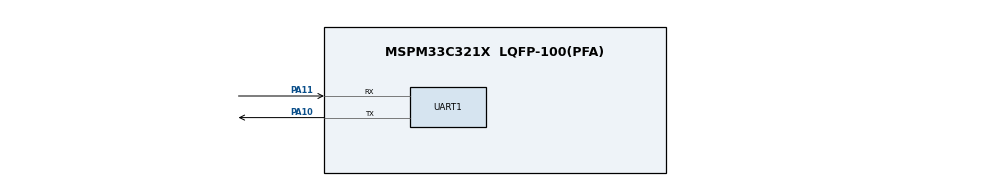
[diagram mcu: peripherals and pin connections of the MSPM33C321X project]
/**
 * @cliArgs --device "MSPM33C321X" --part "Default" --package "LQFP-100(PFA)" --product "mspm33_sdk@1.02.00.00"
 * @versions {"tool":"1.26.0+4407"}
 */
// @cliArgs --board /ti/boards/LP_MSPM33C321A --rtos nortos

/**
 * Import the modules used in this configuration.
 */
const DMA           = scripting.addModule("/ti/driverlib/DMA", {}, false);
const DMA1          = DMA.addInstance();
const GPIO          = scripting.addModule("/ti/driverlib/GPIO", {}, false);
const GPIO1         = GPIO.addInstance();
const HSADC         = scripting.addModule("/ti/driverlib/HSADC", {}, false);
const HSADC1        = HSADC.addInstance();
const SYSCTL        = scripting.addModule("/ti/driverlib/SYSCTL");
const TIMER         = scripting.addModule("/ti/driverlib/TIMER", {}, false);
const TIMER1        = TIMER.addInstance();
const UART          = scripting.addModule("/ti/driverlib/UART", {}, false);
const UART1         = UART.addInstance();
const ProjectConfig = scripting.addModule("/ti/project_config/ProjectConfig");

/**
 * Write custom configuration values to the imported modules.
 */
DMA1.$name                                    = "DMA0";
DMA1.associatedChannels.create(1);
DMA1.associatedChannels[0].$name              = "CH0";
DMA1.associatedChannels[0].triggerSelect      = "ADC0";
DMA1.associatedChannels[0].addressMode        = "f2b";
DMA1.associatedChannels[0].transferMode       = "FULL_CH_REPEAT_SINGLE";
DMA1.associatedChannels[0].destIncrement      = "INCREMENT";
DMA1.associatedChannels[0].enableInterrupt    = true;
DMA1.associatedChannels[0].peripheral.$assign = "DMA0_CH0";

const Board = scripting.addModule("/ti/driverlib/Board", {}, false);

GPIO1.$name                               = "GPIO_GRP_0";
GPIO1.associatedPins[0].$name             = "PIN_0";
GPIO1.associatedPins[0].launchPadShortcut = "LED2RedEn";

HSADC1.$name                             = "HSADC0";
HSADC1.enabledSEQs                       = ["ADC_SEQ_NUMBER1"];
HSADC1.enabledDMAInts                    = ["ADC_INT_NUMBER_1"];
HSADC1.enableDMAInterrupt1               = true;
HSADC1.seq1TriggerSel                    = "ADC_TRIGGER_GEN_SUB_0";
HSADC1.seq1Enable                        = true;
HSADC1.ADCsubscriber1Channel             = 1;
HSADC1.enabledInts                       = ["ADC_INT_NUMBER_1"];
HSADC1.interruptPulseMode                = "ADC_PULSE_END_OF_CONV";
HSADC1.soc0Channel                       = "ADC_CH_ADCIN_7";
HSADC1.enabledSOCs                       = ["ADC_SOC_NUMBER0","ADC_SOC_NUMBER1"];
HSADC1.soc1Channel                       = "ADC_CH_ADCIN_7";
HSADC1.dmaInterrupt1SOCSource            = "ADC_SOC_NUMBER1";
HSADC1.seqEndSOC                         = "ADC_SOC_NUMBER1";
HSADC1.enableDMAInterrupt1ContinuousMode = true;
HSADC1.peripheral.$assign                = "ADC0";
HSADC1.peripheral.adcPin7.$assign        = "PA22";

SYSCTL.MCLKSource    = "HSCLK";
SYSCTL.SYSPLL_Pdiv   = 1;
SYSCTL.SYSPLL_CLK0En = true;

TIMER1.$name                       = "TIMER_0";
TIMER1.event1PublisherChannel      = 1;
TIMER1.timerMode                   = "PERIODIC_UP";
TIMER1.timerClkPrescale            = 100;
TIMER1.event1ControllerInterruptEn = ["LOAD_EVENT"];
TIMER1.timerPeriod                 = "20 us";
TIMER1.peripheral.$assign          = "TIMA0_0";

UART1.$name                    = "UART_0";
UART1.enableFIFO               = true;
UART1.rxFifoThreshold          = "DL_UART_RX_FIFO_LEVEL_ONE_ENTRY";
UART1.txFifoThreshold          = "DL_UART_TX_FIFO_LEVEL_EMPTY";
UART1.enabledInterrupts        = ["RX","TX"];
UART1.targetBaudRate           = 115200;
UART1.peripheral.$assign       = "UC12";
UART1.peripheral.rxPin.$assign = "PA11";
UART1.peripheral.txPin.$assign = "PA10";
UART1.txPinConfig.$name        = "ti_driverlib_gpio_GPIOPinGeneric0";
UART1.rxPinConfig.$name        = "ti_driverlib_gpio_GPIOPinGeneric1";

ProjectConfig.genLibCMSIS = true;

/**
 * Pinmux solution for unlocked pins/peripherals. This ensures that minor changes to the automatic solver in a future
 * version of the tool will not impact the pinmux you originally saw.  These lines can be completely deleted in order to
 * re-solve from scratch.
 */
Board.peripheral.$suggestSolution            = "DEBUGSS";
Board.peripheral.swclkPin.$suggestSolution   = "PA20";
Board.peripheral.swdioPin.$suggestSolution   = "PA19";
GPIO1.associatedPins[0].pin.$suggestSolution = "PC26";
SYSCTL.peripheral.$suggestSolution           = "SYSCTL";
